# ESP32-H21 register map
Vendor: ESPRESSIF SYSTEMS (SHANGHAI) CO., LTD.; Series: ESP32 H-Series; File version: 1
CPU: RV32IMAC r0p0, little endian, no MPU, no FPU, 0 interrupt priority bits
Address unit: 32 bits
Registers are 32-bit, read-write, reset 0x0 unless marked. A register's access mark holds for its fields unless they carry their own. Offsets are from the block's base; [hi:lo] are bit positions; {n}, {i} and the like mark numbered series.

## CACHE (part 3 of 3) — CACHE Peripheral
Base 0x600C8000
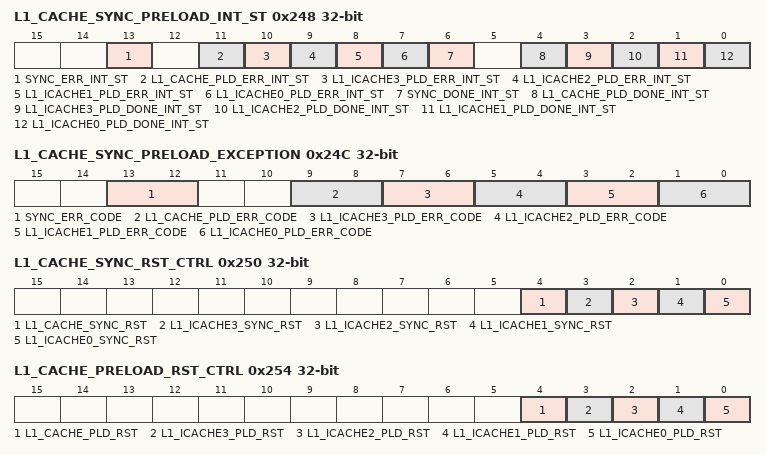
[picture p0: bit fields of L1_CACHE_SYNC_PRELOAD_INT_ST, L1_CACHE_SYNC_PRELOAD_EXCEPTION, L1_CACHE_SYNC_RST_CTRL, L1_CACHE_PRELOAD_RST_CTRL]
0x248 L1_CACHE_SYNC_PRELOAD_INT_ST ro — Sync and preloading operation interrupt status register
  [13] SYNC_ERR_INT_ST — The masked interrupt status of CACHE_SYNC_ERR_INT.
  [11] L1_CACHE_PLD_ERR_INT_ST — The masked interrupt status of L1_CACHE_PLD_ERR_INT.
  [10] L1_ICACHE3_PLD_ERR_INT_ST — Reserved
  [9] L1_ICACHE2_PLD_ERR_INT_ST — Reserved
  [8] L1_ICACHE1_PLD_ERR_INT_ST — The bit indicates the status of the interrupt of L1-ICache1 preload-operation error.
  [7] L1_ICACHE0_PLD_ERR_INT_ST — The bit indicates the status of the interrupt of L1-ICache0 preload-operation error.
  [6] SYNC_DONE_INT_ST — The masked interrupt status of CACHE_SYNC_DONE_INT.
  [4] L1_CACHE_PLD_DONE_INT_ST — The masked interrupt status of L1_CACHE_PLD_DONE_INT.
  [3] L1_ICACHE3_PLD_DONE_INT_ST — Reserved
  [2] L1_ICACHE2_PLD_DONE_INT_ST — Reserved
  [1] L1_ICACHE1_PLD_DONE_INT_ST — The bit indicates the status of the interrupt that occurs only when L1-ICache1 preload-operation is done.
  [0] L1_ICACHE0_PLD_DONE_INT_ST — The bit indicates the status of the interrupt that occurs only when L1-ICache0 preload-operation is done.
0x24C L1_CACHE_SYNC_PRELOAD_EXCEPTION ro — Cache sync and preloading operation exception register
  [13:12] SYNC_ERR_CODE — Represents the error code for the failed synchronization operation.\\ 0: Incorrect synchronization map\\ 1: Synchronization command conflict\\ 2: Incorrect synchronization size\\ 3: Reserved\\
  [9:8] L1_CACHE_PLD_ERR_CODE — Represents the error code for the failed preloading operation.\\ 2: The preloading size in the L1 cache is wrong\\ Other values: reserved\\
  [7:6] L1_ICACHE3_PLD_ERR_CODE — Reserved
  [5:4] L1_ICACHE2_PLD_ERR_CODE — Reserved
  [3:2] L1_ICACHE1_PLD_ERR_CODE — The value 2 is Only available which means preload size is error in L1-ICache1.
  [1:0] L1_ICACHE0_PLD_ERR_CODE — The value 2 is Only available which means preload size is error in L1-ICache0.
0x250 L1_CACHE_SYNC_RST_CTRL — Cache sync reset control register
  [4] L1_CACHE_SYNC_RST — Configures whether to reset the synchronization logic inside the L1 cache.\\ 0: Not reset\\ 1: Reset\\ It is recommended that this field should only be used when a fatal error of the synchronization logic occurs. \\
  [3] L1_ICACHE3_SYNC_RST — Reserved
  [2] L1_ICACHE2_SYNC_RST — Reserved
  [1] L1_ICACHE1_SYNC_RST — set this bit to reset sync-logic inside L1-ICache1. Recommend that this should only be used to initialize sync-logic when some fatal error of sync-logic occurs.
  [0] L1_ICACHE0_SYNC_RST — set this bit to reset sync-logic inside L1-ICache0. Recommend that this should only be used to initialize sync-logic when some fatal error of sync-logic occurs.
0x254 L1_CACHE_PRELOAD_RST_CTRL — Cache preloading reset control register
  [4] L1_CACHE_PLD_RST — Configures whether to reset the preloading logic inside the L1 cache.\\ 0: Not reset\\ 1: Reset\\ It is recommended that this field should only be used when a fatal error of the preloading logic occurs. \\
  [3] L1_ICACHE3_PLD_RST — Reserved
  [2] L1_ICACHE2_PLD_RST — Reserved
  [1] L1_ICACHE1_PLD_RST — set this bit to reset preload-logic inside L1-ICache1. Recommend that this should only be used to initialize preload-logic when some fatal error of preload-logic occurs.
  [0] L1_ICACHE0_PLD_RST — set this bit to reset preload-logic inside L1-ICache0. Recommend that this should only be used to initialize preload-logic when some fatal error of preload-logic occurs.
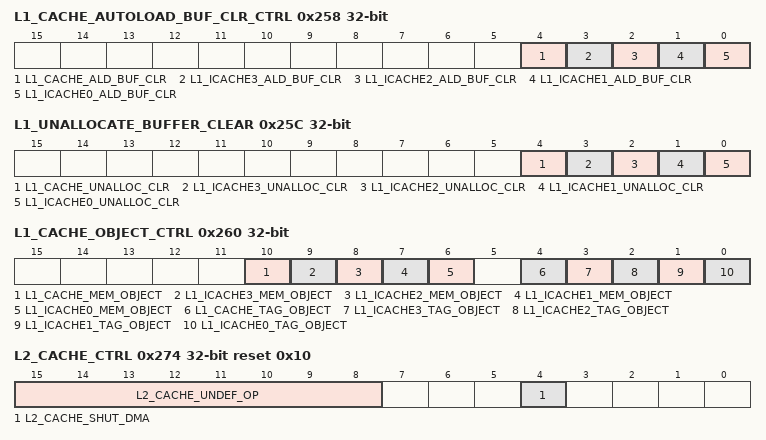
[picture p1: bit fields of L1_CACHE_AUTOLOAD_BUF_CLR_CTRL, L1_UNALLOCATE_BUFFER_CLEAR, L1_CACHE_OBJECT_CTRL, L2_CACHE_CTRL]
0x258 L1_CACHE_AUTOLOAD_BUF_CLR_CTRL — Cache autoloading buffer clear control register
  [4] L1_CACHE_ALD_BUF_CLR — Configures whether to clear the autoloading buffer inside the L1 cache. \\ 0: Not clear the buffer. Recommended when autoloading of L1 cache is used.\\ 1: Clear the buffer. Once set, autoloading of L1 cache will stop working. \\
  [3] L1_ICACHE3_ALD_BUF_CLR — Reserved
  [2] L1_ICACHE2_ALD_BUF_CLR — Reserved
  [1] L1_ICACHE1_ALD_BUF_CLR — set this bit to clear autoload-buffer inside L1-ICache1. If this bit is active, autoload will not work in L1-ICache1. This bit should not be active when autoload works in L1-ICache1.
  [0] L1_ICACHE0_ALD_BUF_CLR — set this bit to clear autoload-buffer inside L1-ICache0. If this bit is active, autoload will not work in L1-ICache0. This bit should not be active when autoload works in L1-ICache0.
0x25C L1_UNALLOCATE_BUFFER_CLEAR — Unallocate request buffer clear registers
  [4] L1_CACHE_UNALLOC_CLR — The bit is used to clear the unallocate request buffer of l1 Cache where the unallocate request is responsed but not completed.
  [3] L1_ICACHE3_UNALLOC_CLR — Reserved
  [2] L1_ICACHE2_UNALLOC_CLR — Reserved
  [1] L1_ICACHE1_UNALLOC_CLR — The bit is used to clear the unallocate request buffer of l1 icache1 where the unallocate request is responsed but not completed.
  [0] L1_ICACHE0_UNALLOC_CLR — The bit is used to clear the unallocate request buffer of l1 icache0 where the unallocate request is responsed but not completed.
0x260 L1_CACHE_OBJECT_CTRL — Cache tag and data memory object control register
  [10] L1_CACHE_MEM_OBJECT — Configures whether to set the L1 cache data memory as an object. \\ 0: Not set\\ 1: Set\\ This field should be one-hot with the other fields inside this register. \\
  [9] L1_ICACHE3_MEM_OBJECT — Reserved
  [8] L1_ICACHE2_MEM_OBJECT — Reserved
  [7] L1_ICACHE1_MEM_OBJECT — Set this bit to set L1-ICache1 data memory as object. This bit should be onehot with the others fields inside this register.
  [6] L1_ICACHE0_MEM_OBJECT — Set this bit to set L1-ICache0 data memory as object. This bit should be onehot with the others fields inside this register.
  [4] L1_CACHE_TAG_OBJECT — Configures whether to set the L1 cache tag memory as an object.\\ 0: Not set\\ 1: Set\\ This field should be one-hot with the other fields inside this register.\\
  [3] L1_ICACHE3_TAG_OBJECT — Reserved
  [2] L1_ICACHE2_TAG_OBJECT — Reserved
  [1] L1_ICACHE1_TAG_OBJECT — Set this bit to set L1-ICache1 tag memory as object. This bit should be onehot with the others fields inside this register.
  [0] L1_ICACHE0_TAG_OBJECT — Set this bit to set L1-ICache0 tag memory as object. This bit should be onehot with the others fields inside this register.
0x264 L1_CACHE_WAY_OBJECT — Cache tag and data memory way register
  [2:0] L1_CACHE_WAY_OBJECT — Configures which way in the tag memory or the data memory to access.\\ 0: Way 0\\ 1: Way 1\\
0x268 L1_CACHE_ADDR reset 0x40000000 — Cache address register
  [31:0] L1_CACHE_ADDR — Configures the virtual address that decides where inside the tag memory or data memory will be accessed.
0x26C L1_CACHE_DEBUG_BUS reset 0x26C — Cache tag and data memory content register
  [31:0] L1_CACHE_DEBUG_BUS — Configures the data to write to or the data to read from the tag memory or the data memory.
0x270 LEVEL_SPLIT0 ro reset 0x270 — USED TO SPLIT L1 CACHE AND L2 CACHE
  [31:0] LEVEL_SPLIT0 — Reserved
0x274 L2_CACHE_CTRL ro reset 0x10 — L2 Cache(L2-Cache) control register
  [15:8] L2_CACHE_UNDEF_OP — Reserved
  [4] L2_CACHE_SHUT_DMA — The bit is used to disable DMA access L2-Cache, 0: enable, 1: disable
0x278 L2_BYPASS_CACHE_CONF ro — Bypass Cache configure register
  [5] BYPASS_L2_CACHE_EN — The bit is used to enable bypass L2-Cache. 0: disable bypass, 1: enable bypass.
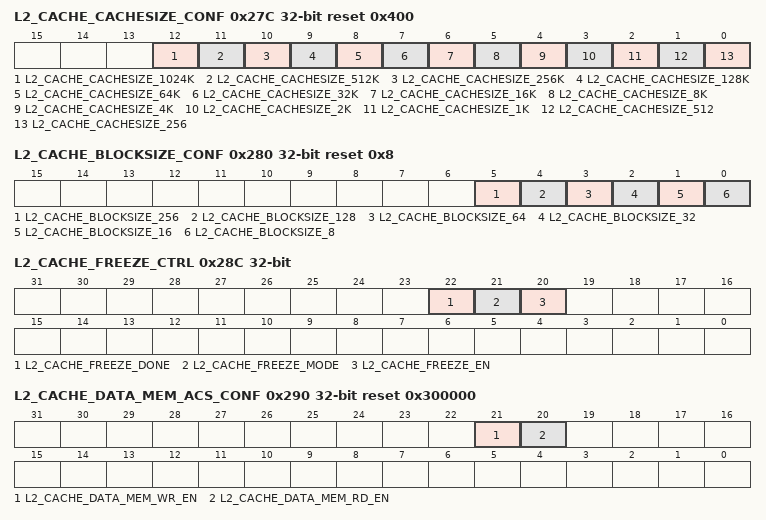
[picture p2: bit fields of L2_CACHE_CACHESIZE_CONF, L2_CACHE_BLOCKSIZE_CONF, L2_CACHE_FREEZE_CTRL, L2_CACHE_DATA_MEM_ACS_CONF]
0x27C L2_CACHE_CACHESIZE_CONF ro reset 0x400 — L2 Cache CacheSize mode configure register
  [12] L2_CACHE_CACHESIZE_1024K — The field is used to configure cachesize of L2-Cache as 1024k bytes. This field and all other fields within this register is onehot.
  [11] L2_CACHE_CACHESIZE_512K — The field is used to configure cachesize of L2-Cache as 512k bytes. This field and all other fields within this register is onehot.
  [10] L2_CACHE_CACHESIZE_256K — The field is used to configure cachesize of L2-Cache as 256k bytes. This field and all other fields within this register is onehot.
  [9] L2_CACHE_CACHESIZE_128K — The field is used to configure cachesize of L2-Cache as 128k bytes. This field and all other fields within this register is onehot.
  [8] L2_CACHE_CACHESIZE_64K — The field is used to configure cachesize of L2-Cache as 64k bytes. This field and all other fields within this register is onehot.
  [7] L2_CACHE_CACHESIZE_32K — The field is used to configure cachesize of L2-Cache as 32k bytes. This field and all other fields within this register is onehot.
  [6] L2_CACHE_CACHESIZE_16K — The field is used to configure cachesize of L2-Cache as 16k bytes. This field and all other fields within this register is onehot.
  [5] L2_CACHE_CACHESIZE_8K — The field is used to configure cachesize of L2-Cache as 8k bytes. This field and all other fields within this register is onehot.
  [4] L2_CACHE_CACHESIZE_4K — The field is used to configure cachesize of L2-Cache as 4k bytes. This field and all other fields within this register is onehot.
  [3] L2_CACHE_CACHESIZE_2K — The field is used to configure cachesize of L2-Cache as 2k bytes. This field and all other fields within this register is onehot.
  [2] L2_CACHE_CACHESIZE_1K — The field is used to configure cachesize of L2-Cache as 1k bytes. This field and all other fields within this register is onehot.
  [1] L2_CACHE_CACHESIZE_512 — The field is used to configure cachesize of L2-Cache as 512 bytes. This field and all other fields within this register is onehot.
  [0] L2_CACHE_CACHESIZE_256 — The field is used to configure cachesize of L2-Cache as 256 bytes. This field and all other fields within this register is onehot.
0x280 L2_CACHE_BLOCKSIZE_CONF ro reset 0x8 — L2 Cache BlockSize mode configure register
  [5] L2_CACHE_BLOCKSIZE_256 — The field is used to configureblocksize of L2-Cache as 256 bytes. This field and all other fields within this register is onehot.
  [4] L2_CACHE_BLOCKSIZE_128 — The field is used to configureblocksize of L2-Cache as 128 bytes. This field and all other fields within this register is onehot.
  [3] L2_CACHE_BLOCKSIZE_64 — The field is used to configureblocksize of L2-Cache as 64 bytes. This field and all other fields within this register is onehot.
  [2] L2_CACHE_BLOCKSIZE_32 — The field is used to configureblocksize of L2-Cache as 32 bytes. This field and all other fields within this register is onehot.
  [1] L2_CACHE_BLOCKSIZE_16 — The field is used to configureblocksize of L2-Cache as 16 bytes. This field and all other fields within this register is onehot.
  [0] L2_CACHE_BLOCKSIZE_8 — The field is used to configureblocksize of L2-Cache as 8 bytes. This field and all other fields within this register is onehot.
0x284 L2_CACHE_WRAP_AROUND_CTRL ro — Cache wrap around control register
  [5] L2_CACHE_WRAP — Set this bit as 1 to enable L2-Cache wrap around mode.
0x288 L2_CACHE_MISS_ACCESS_CTRL ro — Cache wrap around control register
  [5] L2_CACHE_MISS_DISABLE_ACCESS — Set this bit as 1 to disable early restart of L2-Cache
0x28C L2_CACHE_FREEZE_CTRL ro — Cache Freeze control register
  [22] L2_CACHE_FREEZE_DONE — The bit is used to indicate whether freeze operation on L2-Cache is finished or not. 0: not finished. 1: finished.
  [21] L2_CACHE_FREEZE_MODE — The bit is used to configure mode of freeze operation L2-Cache. 0: a miss-access will not stuck. 1: a miss-access will stuck.
  [20] L2_CACHE_FREEZE_EN — The bit is used to enable freeze operation on L2-Cache. It can be cleared by software.
0x290 L2_CACHE_DATA_MEM_ACS_CONF ro reset 0x300000 — Cache data memory access configure register
  [21] L2_CACHE_DATA_MEM_WR_EN — The bit is used to enable config-bus write L2-Cache data memoryory. 0: disable, 1: enable.
  [20] L2_CACHE_DATA_MEM_RD_EN — The bit is used to enable config-bus read L2-Cache data memoryory. 0: disable, 1: enable.
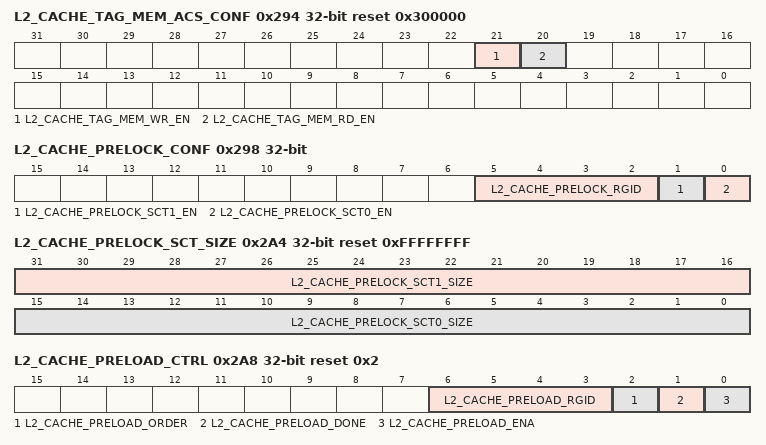
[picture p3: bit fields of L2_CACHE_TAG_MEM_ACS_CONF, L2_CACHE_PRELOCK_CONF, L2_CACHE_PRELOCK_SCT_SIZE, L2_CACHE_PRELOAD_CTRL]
0x294 L2_CACHE_TAG_MEM_ACS_CONF ro reset 0x300000 — Cache tag memory access configure register
  [21] L2_CACHE_TAG_MEM_WR_EN — The bit is used to enable config-bus write L2-Cache tag memoryory. 0: disable, 1: enable.
  [20] L2_CACHE_TAG_MEM_RD_EN — The bit is used to enable config-bus read L2-Cache tag memoryory. 0: disable, 1: enable.
0x298 L2_CACHE_PRELOCK_CONF ro — L2 Cache prelock configure register
  [5:2] L2_CACHE_PRELOCK_RGID — The bit is used to set the gid of l2 cache prelock.
  [1] L2_CACHE_PRELOCK_SCT1_EN — The bit is used to enable the second section of prelock function on L2-Cache.
  [0] L2_CACHE_PRELOCK_SCT0_EN — The bit is used to enable the first section of prelock function on L2-Cache.
0x29C L2_CACHE_PRELOCK_SCT0_ADDR ro — L2 Cache prelock section0 address configure register
  [31:0] L2_CACHE_PRELOCK_SCT0_ADDR — Those bits are used to configure the start address of the first section of prelock on L2-Cache, which should be used together with L2_CACHE_PRELOCK_SCT0_SIZE_REG
0x2A0 L2_CACHE_PRELOCK_SCT1_ADDR ro — L2 Cache prelock section1 address configure register
  [31:0] L2_CACHE_PRELOCK_SCT1_ADDR — Those bits are used to configure the start address of the second section of prelock on L2-Cache, which should be used together with L2_CACHE_PRELOCK_SCT1_SIZE_REG
0x2A4 L2_CACHE_PRELOCK_SCT_SIZE ro reset 0xFFFFFFFF — L2 Cache prelock section size configure register
  [31:16] L2_CACHE_PRELOCK_SCT1_SIZE — Those bits are used to configure the size of the second section of prelock on L2-Cache, which should be used together with L2_CACHE_PRELOCK_SCT1_ADDR_REG
  [15:0] L2_CACHE_PRELOCK_SCT0_SIZE — Those bits are used to configure the size of the first section of prelock on L2-Cache, which should be used together with L2_CACHE_PRELOCK_SCT0_ADDR_REG
0x2A8 L2_CACHE_PRELOAD_CTRL access per field reset 0x2 — L2 Cache preload-operation control register
  [6:3] L2_CACHE_PRELOAD_RGID ro — The bit is used to set the gid of l2 cache preload.
  [2] L2_CACHE_PRELOAD_ORDER ro — The bit is used to configure the direction of preload operation. 0: ascending, 1: descending.
  [1] L2_CACHE_PRELOAD_DONE ro — The bit is used to indicate whether preload operation is finished or not. 0: not finished. 1: finished.
  [0] L2_CACHE_PRELOAD_ENA rw — The bit is used to enable preload operation on L2-Cache. It will be cleared by hardware automatically after preload operation is done.
0x2AC L2_CACHE_PRELOAD_ADDR ro — L2 Cache preload address configure register
  [31:0] L2_CACHE_PRELOAD_ADDR — Those bits are used to configure the start address of preload on L2-Cache, which should be used together with L2_CACHE_PRELOAD_SIZE_REG
0x2B0 L2_CACHE_PRELOAD_SIZE ro — L2 Cache preload size configure register
  [15:0] L2_CACHE_PRELOAD_SIZE — Those bits are used to configure the size of the first section of prelock on L2-Cache, which should be used together with L2_CACHE_PRELOAD_ADDR_REG
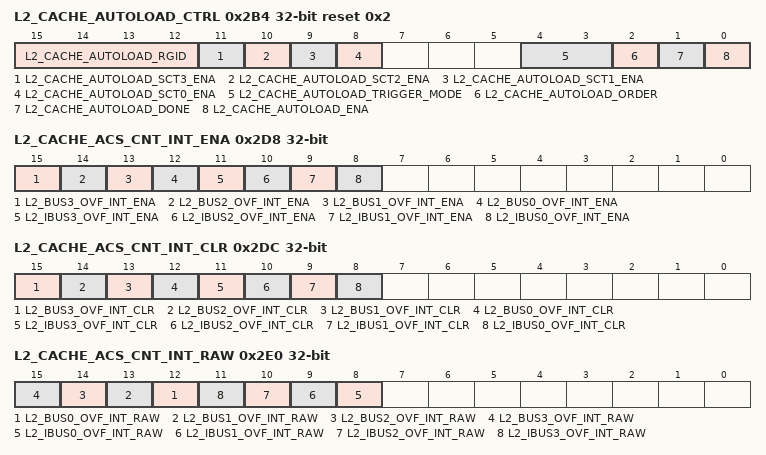
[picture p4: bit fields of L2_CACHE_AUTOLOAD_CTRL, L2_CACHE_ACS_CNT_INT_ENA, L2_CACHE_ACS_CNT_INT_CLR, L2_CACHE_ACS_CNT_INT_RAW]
0x2B4 L2_CACHE_AUTOLOAD_CTRL ro reset 0x2 — L2 Cache autoload-operation control register
  [15:12] L2_CACHE_AUTOLOAD_RGID — The bit is used to set the gid of l2 cache autoload.
  [11] L2_CACHE_AUTOLOAD_SCT3_ENA — The bit is used to enable the fourth section for autoload operation on L2-Cache.
  [10] L2_CACHE_AUTOLOAD_SCT2_ENA — The bit is used to enable the third section for autoload operation on L2-Cache.
  [9] L2_CACHE_AUTOLOAD_SCT1_ENA — The bit is used to enable the second section for autoload operation on L2-Cache.
  [8] L2_CACHE_AUTOLOAD_SCT0_ENA — The bit is used to enable the first section for autoload operation on L2-Cache.
  [4:3] L2_CACHE_AUTOLOAD_TRIGGER_MODE — The field is used to configure trigger mode of autoload operation on L2-Cache. 0/3: miss-trigger, 1: hit-trigger, 2: miss-hit-trigger.
  [2] L2_CACHE_AUTOLOAD_ORDER — The bit is used to configure the direction of autoload operation on L2-Cache. 0: ascending. 1: descending.
  [1] L2_CACHE_AUTOLOAD_DONE — The bit is used to indicate whether autoload operation on L2-Cache is finished or not. 0: not finished. 1: finished.
  [0] L2_CACHE_AUTOLOAD_ENA — The bit is used to enable and disable autoload operation on L2-Cache. 1: enable, 0: disable.
0x2B8 L2_CACHE_AUTOLOAD_SCT0_ADDR ro — L2 Cache autoload section 0 address configure register
  [31:0] L2_CACHE_AUTOLOAD_SCT0_ADDR — Those bits are used to configure the start address of the first section for autoload operation on L2-Cache. Note that it should be used together with L2_CACHE_AUTOLOAD_SCT0_SIZE and L2_CACHE_AUTOLOAD_SCT0_ENA.
0x2BC L2_CACHE_AUTOLOAD_SCT0_SIZE ro — L2 Cache autoload section 0 size configure register
  [27:0] L2_CACHE_AUTOLOAD_SCT0_SIZE — Those bits are used to configure the size of the first section for autoload operation on L2-Cache. Note that it should be used together with L2_CACHE_AUTOLOAD_SCT0_ADDR and L2_CACHE_AUTOLOAD_SCT0_ENA.
0x2C0 L2_CACHE_AUTOLOAD_SCT1_ADDR ro — L2 Cache autoload section 1 address configure register
  [31:0] L2_CACHE_AUTOLOAD_SCT1_ADDR — Those bits are used to configure the start address of the second section for autoload operation on L2-Cache. Note that it should be used together with L2_CACHE_AUTOLOAD_SCT1_SIZE and L2_CACHE_AUTOLOAD_SCT1_ENA.
0x2C4 L2_CACHE_AUTOLOAD_SCT1_SIZE ro — L2 Cache autoload section 1 size configure register
  [27:0] L2_CACHE_AUTOLOAD_SCT1_SIZE — Those bits are used to configure the size of the second section for autoload operation on L2-Cache. Note that it should be used together with L2_CACHE_AUTOLOAD_SCT1_ADDR and L2_CACHE_AUTOLOAD_SCT1_ENA.
0x2C8 L2_CACHE_AUTOLOAD_SCT2_ADDR — L2 Cache autoload section 2 address configure register
  [31:0] L2_CACHE_AUTOLOAD_SCT2_ADDR — Those bits are used to configure the start address of the third section for autoload operation on L2-Cache. Note that it should be used together with L2_CACHE_AUTOLOAD_SCT2_SIZE and L2_CACHE_AUTOLOAD_SCT2_ENA.
0x2CC L2_CACHE_AUTOLOAD_SCT2_SIZE ro — L2 Cache autoload section 2 size configure register
  [27:0] L2_CACHE_AUTOLOAD_SCT2_SIZE — Those bits are used to configure the size of the third section for autoload operation on L2-Cache. Note that it should be used together with L2_CACHE_AUTOLOAD_SCT2_ADDR and L2_CACHE_AUTOLOAD_SCT2_ENA.
0x2D0 L2_CACHE_AUTOLOAD_SCT3_ADDR ro — L2 Cache autoload section 3 address configure register
  [31:0] L2_CACHE_AUTOLOAD_SCT3_ADDR — Those bits are used to configure the start address of the fourth section for autoload operation on L2-Cache. Note that it should be used together with L2_CACHE_AUTOLOAD_SCT3_SIZE and L2_CACHE_AUTOLOAD_SCT3_ENA.
0x2D4 L2_CACHE_AUTOLOAD_SCT3_SIZE ro — L2 Cache autoload section 3 size configure register
  [27:0] L2_CACHE_AUTOLOAD_SCT3_SIZE — Those bits are used to configure the size of the fourth section for autoload operation on L2-Cache. Note that it should be used together with L2_CACHE_AUTOLOAD_SCT3_ADDR and L2_CACHE_AUTOLOAD_SCT3_ENA.
0x2D8 L2_CACHE_ACS_CNT_INT_ENA access per field — Cache Access Counter Interrupt enable register
  [15] L2_BUS3_OVF_INT_ENA ro — Reserved
  [14] L2_BUS2_OVF_INT_ENA ro — Reserved
  [13] L2_BUS1_OVF_INT_ENA ro — The bit is used to enable interrupt of one of counters overflow that occurs in L2-Cache due to bus1 accesses L2-Cache.
  [12] L2_BUS0_OVF_INT_ENA ro — The bit is used to enable interrupt of one of counters overflow that occurs in L2-Cache due to bus0 accesses L2-Cache.
  [11] L2_IBUS3_OVF_INT_ENA ro — Reserved
  [10] L2_IBUS2_OVF_INT_ENA ro — Reserved
  [9] L2_IBUS1_OVF_INT_ENA rw — The bit is used to enable interrupt of one of counters overflow that occurs in L2-Cache due to bus1 accesses L2-Cache.
  [8] L2_IBUS0_OVF_INT_ENA rw — The bit is used to enable interrupt of one of counters overflow that occurs in L2-Cache due to bus0 accesses L2-Cache.
0x2DC L2_CACHE_ACS_CNT_INT_CLR access per field — Cache Access Counter Interrupt clear register
  [15] L2_BUS3_OVF_INT_CLR ro — Reserved
  [14] L2_BUS2_OVF_INT_CLR ro — Reserved
  [13] L2_BUS1_OVF_INT_CLR wo — The bit is used to clear counters overflow interrupt and counters in L2-Cache due to bus1 accesses L2-Cache.
  [12] L2_BUS0_OVF_INT_CLR wo — The bit is used to clear counters overflow interrupt and counters in L2-Cache due to bus0 accesses L2-Cache.
  [11] L2_IBUS3_OVF_INT_CLR ro — Reserved
  [10] L2_IBUS2_OVF_INT_CLR ro — Reserved
  [9] L2_IBUS1_OVF_INT_CLR wo — The bit is used to clear counters overflow interrupt and counters in L2-Cache due to bus1 accesses L2-Cache.
  [8] L2_IBUS0_OVF_INT_CLR wo — The bit is used to clear counters overflow interrupt and counters in L2-Cache due to bus0 accesses L2-Cache.
0x2E0 L2_CACHE_ACS_CNT_INT_RAW — Cache Access Counter Interrupt raw register
  [n+12] L2_BUS{n}_OVF_INT_RAW (n=0..3) — The raw bit of the interrupt of one of counters overflow that occurs in L2-Cache due to bus{n} accesses L2-Cache.
  [n+8] L2_IBUS{n}_OVF_INT_RAW (n=0..3) — The raw bit of the interrupt of one of counters overflow that occurs in L2-Cache due to bus{n} accesses L2-ICache{n}.
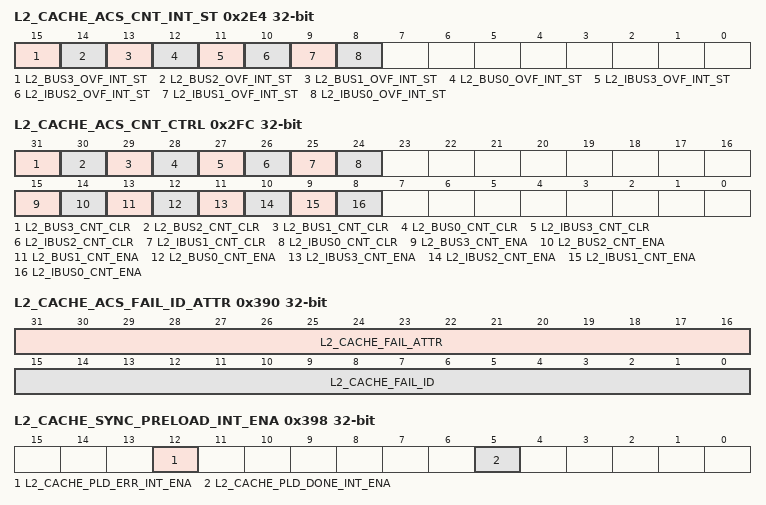
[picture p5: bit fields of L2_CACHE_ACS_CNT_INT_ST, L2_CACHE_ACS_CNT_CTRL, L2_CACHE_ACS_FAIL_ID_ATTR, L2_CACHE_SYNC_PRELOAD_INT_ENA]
0x2E4 L2_CACHE_ACS_CNT_INT_ST ro — Cache Access Counter Interrupt status register
  [15] L2_BUS3_OVF_INT_ST — Reserved
  [14] L2_BUS2_OVF_INT_ST — Reserved
  [13] L2_BUS1_OVF_INT_ST — The bit indicates the interrupt status of one of counters overflow that occurs in L2-Cache due to bus1 accesses L2-Cache.
  [12] L2_BUS0_OVF_INT_ST — The bit indicates the interrupt status of one of counters overflow that occurs in L2-Cache due to bus0 accesses L2-Cache.
  [11] L2_IBUS3_OVF_INT_ST — Reserved
  [10] L2_IBUS2_OVF_INT_ST — Reserved
  [9] L2_IBUS1_OVF_INT_ST — The bit indicates the interrupt status of one of counters overflow that occurs in L2-Cache due to bus1 accesses L2-Cache.
  [8] L2_IBUS0_OVF_INT_ST — The bit indicates the interrupt status of one of counters overflow that occurs in L2-Cache due to bus0 accesses L2-Cache.
0x2E8 L2_CACHE_ACS_FAIL_CTRL ro — Cache Access Fail Configuration register
  [0] L2_CACHE_ACS_FAIL_CHECK_MODE — The bit is used to configure l2 cache access fail check mode. 0: the access fail is not propagated to the request, 1: the access fail is propagated to the request
0x2EC L2_CACHE_ACS_FAIL_INT_ENA ro — Cache Access Fail Interrupt enable register
  [5] L2_CACHE_FAIL_INT_ENA — The bit is used to enable interrupt of access fail that occurs in L2-Cache due to l1 cache accesses L2-Cache.
0x2F0 L2_CACHE_ACS_FAIL_INT_CLR wo — L1-Cache Access Fail Interrupt clear register
  [5] L2_CACHE_FAIL_INT_CLR — The bit is used to clear interrupt of access fail that occurs in L2-Cache due to l1 cache accesses L2-Cache.
0x2F4 L2_CACHE_ACS_FAIL_INT_RAW — Cache Access Fail Interrupt raw register
  [5] L2_CACHE_FAIL_INT_RAW — The raw bit of the interrupt of access fail that occurs in L2-Cache.
0x2F8 L2_CACHE_ACS_FAIL_INT_ST ro — Cache Access Fail Interrupt status register
  [5] L2_CACHE_FAIL_INT_ST — The bit indicates the interrupt status of access fail that occurs in L2-Cache due to l1 cache accesses L2-Cache.
0x2FC L2_CACHE_ACS_CNT_CTRL access per field — Cache Access Counter enable and clear register
  [31] L2_BUS3_CNT_CLR ro — Reserved
  [30] L2_BUS2_CNT_CLR ro — Reserved
  [29] L2_BUS1_CNT_CLR wo — The bit is used to clear dbus1 counter in L2-Cache.
  [28] L2_BUS0_CNT_CLR wo — The bit is used to clear dbus0 counter in L2-Cache.
  [27] L2_IBUS3_CNT_CLR ro — Reserved
  [26] L2_IBUS2_CNT_CLR ro — Reserved
  [25] L2_IBUS1_CNT_CLR wo — The bit is used to clear ibus1 counter in L2-Cache.
  [24] L2_IBUS0_CNT_CLR wo — The bit is used to clear ibus0 counter in L2-Cache.
  [15] L2_BUS3_CNT_ENA ro — Reserved
  [14] L2_BUS2_CNT_ENA ro — Reserved
  [13] L2_BUS1_CNT_ENA ro — The bit is used to enable dbus1 counter in L2-Cache.
  [12] L2_BUS0_CNT_ENA ro — The bit is used to enable dbus0 counter in L2-Cache.
  [11] L2_IBUS3_CNT_ENA ro — Reserved
  [10] L2_IBUS2_CNT_ENA ro — Reserved
  [9] L2_IBUS1_CNT_ENA ro — The bit is used to enable ibus1 counter in L2-Cache.
  [8] L2_IBUS0_CNT_ENA ro — The bit is used to enable ibus0 counter in L2-Cache.
{0x300+0x10*i} L2_IBUS{i}_ACS_HIT_CNT ro (i=0..3) — L2-Cache bus{i} Hit-Access Counter register
  [31:0] L2_IBUS{i}_HIT_CNT — The register records the number of hits when L1-ICache{i} accesses L2-Cache due to bus{i} accessing L1-ICache{i}.
{0x304+0x10*i} L2_IBUS{i}_ACS_MISS_CNT ro (i=0..3) — L2-Cache bus{i} Miss-Access Counter register
  [31:0] L2_IBUS{i}_MISS_CNT — The register records the number of missing when L1-ICache{i} accesses L2-Cache due to bus{i} accessing L1-ICache{i}.
{0x308+0x10*i} L2_IBUS{i}_ACS_CONFLICT_CNT ro (i=0..3) — L2-Cache bus{i} Conflict-Access Counter register
  [31:0] L2_IBUS{i}_CONFLICT_CNT — The register records the number of access-conflicts when L1-ICache{i} accesses L2-Cache due to bus{i} accessing L1-ICache{i}.
{0x30C+0x10*i} L2_IBUS{i}_ACS_NXTLVL_RD_CNT ro (i=0..3) — L2-Cache bus{i} Next-Level-Access Counter register
  [31:0] L2_IBUS{i}_NXTLVL_RD_CNT — The register records the number of times that L2-Cache accesses external memory due to L1-ICache{i} accessing L2-Cache due to bus{i} accessing L1-ICache{i}.
{0x340+0x14*i} L2_DBUS{i}_ACS_HIT_CNT ro (i=0..3) — L2-Cache bus{i} Hit-Access Counter register
  [31:0] L2_BUS{i}_HIT_CNT — The register records the number of hits when L1-Cache accesses L2-Cache due to bus{i} accessing L1-Cache.
{0x344+0x14*i} L2_DBUS{i}_ACS_MISS_CNT ro (i=0..3) — L2-Cache bus{i} Miss-Access Counter register
  [31:0] L2_BUS{i}_MISS_CNT — The register records the number of missing when L1-Cache accesses L2-Cache due to bus{i} accessing L1-Cache.
{0x348+0x14*i} L2_DBUS{i}_ACS_CONFLICT_CNT ro (i=0..3) — L2-Cache bus{i} Conflict-Access Counter register
  [31:0] L2_BUS{i}_CONFLICT_CNT — The register records the number of access-conflicts when L1-Cache accesses L2-Cache due to bus{i} accessing L1-Cache.
{0x34C+0x14*i} L2_DBUS{i}_ACS_NXTLVL_RD_CNT ro (i=0..3) — L2-Cache bus{i} Next-Level-Access Counter register
  [31:0] L2_BUS{i}_NXTLVL_RD_CNT — The register records the number of times that L2-Cache accesses external memory due to L1-Cache accessing L2-Cache due to bus{i} accessing L1-Cache.
{0x350+0x14*i} L2_DBUS{i}_ACS_NXTLVL_WR_CNT ro (i=0..3) — L2-Cache bus{i} WB-Access Counter register
  [31:0] L2_BUS{i}_NXTLVL_WR_CNT — The register records the number of write back when L1-Cache accesses L2-Cache due to bus{i} accessing L1-Cache.
0x390 L2_CACHE_ACS_FAIL_ID_ATTR ro — L2-Cache Access Fail ID/attribution information register
  [31:16] L2_CACHE_FAIL_ATTR — The register records the attribution of fail-access when L1-Cache accesses L2-Cache due to cache accessing L1-Cache.
  [15:0] L2_CACHE_FAIL_ID — The register records the ID of fail-access when L1-Cache accesses L2-Cache.
0x394 L2_CACHE_ACS_FAIL_ADDR ro — L2-Cache Access Fail Address information register
  [31:0] L2_CACHE_FAIL_ADDR — The register records the address of fail-access when L1-Cache accesses L2-Cache.
0x398 L2_CACHE_SYNC_PRELOAD_INT_ENA ro — L1-Cache Access Fail Interrupt enable register
  [12] L2_CACHE_PLD_ERR_INT_ENA — The bit is used to enable interrupt of L2-Cache preload-operation error.
  [5] L2_CACHE_PLD_DONE_INT_ENA — The bit is used to enable interrupt of L2-Cache preload-operation done.
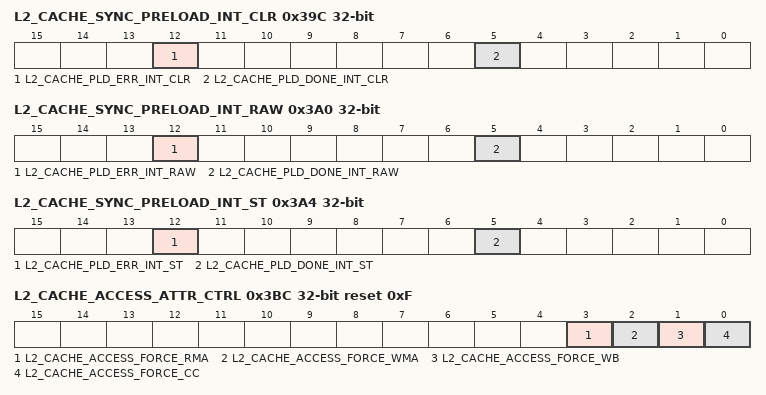
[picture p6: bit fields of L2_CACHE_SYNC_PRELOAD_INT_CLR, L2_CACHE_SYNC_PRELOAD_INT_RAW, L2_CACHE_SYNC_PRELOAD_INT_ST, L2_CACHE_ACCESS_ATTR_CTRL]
0x39C L2_CACHE_SYNC_PRELOAD_INT_CLR wo — Sync Preload operation Interrupt clear register
  [12] L2_CACHE_PLD_ERR_INT_CLR — The bit is used to clear interrupt of L2-Cache preload-operation error.
  [5] L2_CACHE_PLD_DONE_INT_CLR — The bit is used to clear interrupt that occurs only when L2-Cache preload-operation is done.
0x3A0 L2_CACHE_SYNC_PRELOAD_INT_RAW — Sync Preload operation Interrupt raw register
  [12] L2_CACHE_PLD_ERR_INT_RAW — The raw bit of the interrupt that occurs only when L2-Cache preload-operation error occurs.
  [5] L2_CACHE_PLD_DONE_INT_RAW — The raw bit of the interrupt that occurs only when L2-Cache preload-operation is done.
0x3A4 L2_CACHE_SYNC_PRELOAD_INT_ST ro — L1-Cache Access Fail Interrupt status register
  [12] L2_CACHE_PLD_ERR_INT_ST — The bit indicates the status of the interrupt of L2-Cache preload-operation error.
  [5] L2_CACHE_PLD_DONE_INT_ST — The bit indicates the status of the interrupt that occurs only when L2-Cache preload-operation is done.
0x3A8 L2_CACHE_SYNC_PRELOAD_EXCEPTION ro — Cache Sync/Preload Operation exception register
  [11:10] L2_CACHE_PLD_ERR_CODE — The value 2 is Only available which means preload size is error in L2-Cache.
0x3AC L2_CACHE_SYNC_RST_CTRL ro — Cache Sync Reset control register
  [5] L2_CACHE_SYNC_RST — set this bit to reset sync-logic inside L2-Cache. Recommend that this should only be used to initialize sync-logic when some fatal error of sync-logic occurs.
0x3B0 L2_CACHE_PRELOAD_RST_CTRL ro — Cache Preload Reset control register
  [5] L2_CACHE_PLD_RST — set this bit to reset preload-logic inside L2-Cache. Recommend that this should only be used to initialize preload-logic when some fatal error of preload-logic occurs.
0x3B4 L2_CACHE_AUTOLOAD_BUF_CLR_CTRL ro — Cache Autoload buffer clear control register
  [5] L2_CACHE_ALD_BUF_CLR — set this bit to clear autoload-buffer inside L2-Cache. If this bit is active, autoload will not work in L2-Cache. This bit should not be active when autoload works in L2-Cache.
0x3B8 L2_UNALLOCATE_BUFFER_CLEAR ro — Unallocate request buffer clear registers
  [5] L2_CACHE_UNALLOC_CLR — The bit is used to clear the unallocate request buffer of l2 icache where the unallocate request is responsed but not completed.
0x3BC L2_CACHE_ACCESS_ATTR_CTRL ro reset 0xF — L2 cache access attribute control register
  [3] L2_CACHE_ACCESS_FORCE_RMA — Set this bit to force the request to l2 cache with read-miss-allocate attribute, otherwise, the attribute is propagated from L1 cache or CPU, it could be one of read-miss-allocate and read-miss-no-allocate.
  [2] L2_CACHE_ACCESS_FORCE_WMA — Set this bit to force the request to l2 cache with write-miss-allocate attribute, otherwise, the attribute is propagated from L1 cache or CPU, it could be one of write-miss-allocate and write-miss-no-allocate.
  [1] L2_CACHE_ACCESS_FORCE_WB — Set this bit to force the request to l2 cache with write-back attribute, otherwise, the attribute is propagated from L1 cache or CPU, it could be one of write-back and write-through.
  [0] L2_CACHE_ACCESS_FORCE_CC — Set this bit to force the request to l2 cache with cacheable attribute, otherwise, the attribute is propagated from L1 cache or CPU, it could be one of cacheable and non-cacheable.
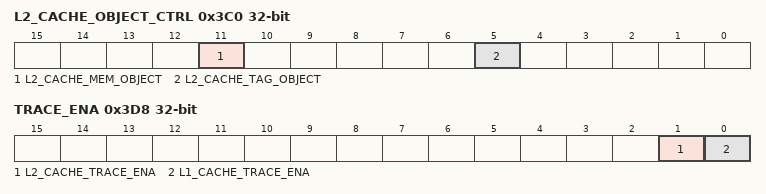
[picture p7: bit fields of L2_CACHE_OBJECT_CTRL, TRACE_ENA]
0x3C0 L2_CACHE_OBJECT_CTRL ro — Cache Tag and Data memory Object control register
  [11] L2_CACHE_MEM_OBJECT — Set this bit to set L2-Cache data memory as object. This bit should be onehot with the others fields inside this register.
  [5] L2_CACHE_TAG_OBJECT — Set this bit to set L2-Cache tag memory as object. This bit should be onehot with the others fields inside this register.
0x3C4 L2_CACHE_WAY_OBJECT ro — Cache Tag and Data memory way register
  [2:0] L2_CACHE_WAY_OBJECT — Set this bits to select which way of the tag-object will be accessed. 0: way0, 1: way1, 2: way2, 3: way3, ?, 7: way7.
0x3C8 L2_CACHE_ADDR ro reset 0x40000000 — Cache address register
  [31:0] L2_CACHE_ADDR — Those bits stores the address which will decide where inside the specified tag memory object will be accessed.
0x3CC L2_CACHE_DEBUG_BUS reset 0x3CC — Cache Tag/data memory content register
  [31:0] L2_CACHE_DEBUG_BUS — This is a constant place where we can write data to or read data from the tag/data memory on the specified cache.
0x3D0 LEVEL_SPLIT1 ro reset 0x3D0 — USED TO SPLIT L1 CACHE AND L2 CACHE
  [31:0] LEVEL_SPLIT1 — Reserved
0x3D4 CLOCK_GATE — Clock gate control register
  [0] CLK_EN — The bit is used to enable clock gate when access all registers in this module.
0x3D8 TRACE_ENA access per field — Clock gate control register
  [1] L2_CACHE_TRACE_ENA ro — The bit is used to enable L2-Cache trace for the performance counter and fail tracer
  [0] L1_CACHE_TRACE_ENA rw — Configures whether to enable the L1 cache trace for the performance counter and failure tracer.\\ 0: Disable\\ 1: Enable\\
{0x3DC+4i} REDUNDANCY_SIG{i} (i=0..3) — Cache redundancy signal {i} register
  [31:0] REDCY_SIG{i} — Those bits are prepared for ECO.
0x3EC REDUNDANCY_SIG4 ro — Cache redundancy signal 0 register
  [3:0] REDCY_SIG4 — Those bits are prepared for ECO.
0x3FC DATE reset 0x2408200 — Version control register
  [27:0] DATE — Version control register. Note that the default value is the latest date when the hardware logic was updated.
